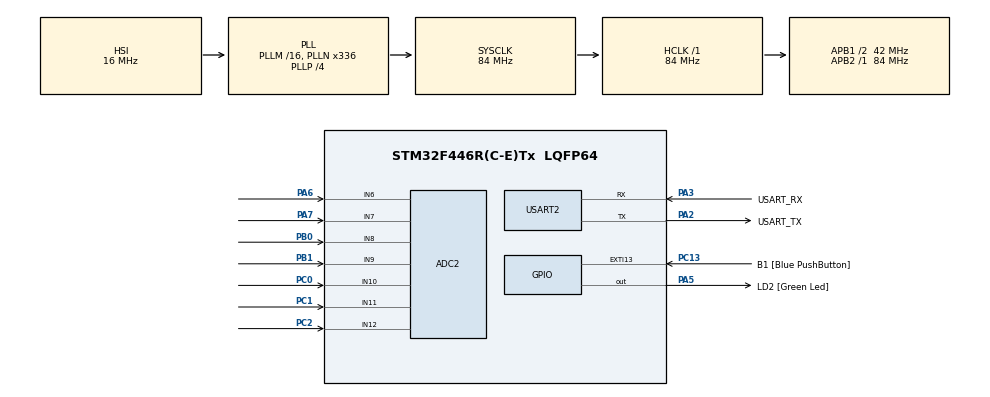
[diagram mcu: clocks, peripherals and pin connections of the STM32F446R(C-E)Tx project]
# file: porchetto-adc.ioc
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ADC2.Channel-2\#ChannelRegularConversion=ADC_CHANNEL_6
ADC2.Channel-3\#ChannelRegularConversion=ADC_CHANNEL_7
ADC2.Channel-4\#ChannelRegularConversion=ADC_CHANNEL_8
ADC2.Channel-5\#ChannelRegularConversion=ADC_CHANNEL_9
ADC2.Channel-6\#ChannelRegularConversion=ADC_CHANNEL_10
ADC2.Channel-7\#ChannelRegularConversion=ADC_CHANNEL_11
ADC2.Channel-8\#ChannelRegularConversion=ADC_CHANNEL_12
ADC2.ContinuousConvMode=DISABLE
ADC2.DMAContinuousRequests=DISABLE
ADC2.EOCSelection=ADC_EOC_SEQ_CONV
ADC2.NbrOfConversion=7
ADC2.NbrOfConversionFlag=1
ADC2.Rank-2\#ChannelRegularConversion=1
ADC2.Rank-3\#ChannelRegularConversion=2
ADC2.Rank-4\#ChannelRegularConversion=3
ADC2.Rank-5\#ChannelRegularConversion=4
ADC2.Rank-6\#ChannelRegularConversion=5
ADC2.Rank-7\#ChannelRegularConversion=6
ADC2.Rank-8\#ChannelRegularConversion=7
ADC2.SamplingTime-2\#ChannelRegularConversion=ADC_SAMPLETIME_28CYCLES
ADC2.SamplingTime-3\#ChannelRegularConversion=ADC_SAMPLETIME_28CYCLES
ADC2.SamplingTime-4\#ChannelRegularConversion=ADC_SAMPLETIME_28CYCLES
ADC2.SamplingTime-5\#ChannelRegularConversion=ADC_SAMPLETIME_28CYCLES
ADC2.SamplingTime-6\#ChannelRegularConversion=ADC_SAMPLETIME_28CYCLES
ADC2.SamplingTime-7\#ChannelRegularConversion=ADC_SAMPLETIME_28CYCLES
ADC2.SamplingTime-8\#ChannelRegularConversion=ADC_SAMPLETIME_28CYCLES
ADC2.ScanConvMode=ENABLE
Dma.ADC2.0.Direction=DMA_PERIPH_TO_MEMORY
Dma.ADC2.0.FIFOMode=DMA_FIFOMODE_DISABLE
Dma.ADC2.0.Instance=DMA2_Stream2
Dma.ADC2.0.MemDataAlignment=DMA_MDATAALIGN_HALFWORD
Dma.ADC2.0.MemInc=DMA_MINC_ENABLE
Dma.ADC2.0.Mode=DMA_NORMAL
Dma.ADC2.0.PeriphDataAlignment=DMA_PDATAALIGN_HALFWORD
Dma.ADC2.0.PeriphInc=DMA_PINC_DISABLE
Dma.ADC2.0.Priority=DMA_PRIORITY_LOW
Dma.Request0=ADC2
Mcu.Family=STM32F4
Mcu.Name=STM32F446R(C-E)Tx
Mcu.Package=LQFP64
NVIC.ADC_IRQn=true\:0\:0\:false\:false\:true\:true\:true\:true
NVIC.DMA2_Stream2_IRQn=true\:0\:0\:false\:false\:true\:false\:true\:true
NVIC.PriorityGroup=NVIC_PRIORITYGROUP_0
PA13.GPIO_Label=TMS
PA13.Mode=Serial_Wire
PA13.Signal=SYS_JTMS-SWDIO
PA14.GPIO_Label=TCK
PA14.Mode=Serial_Wire
PA14.Signal=SYS_JTCK-SWCLK
PA2.GPIO_Label=USART_TX
PA2.Mode=Asynchronous
PA2.Signal=USART2_TX
PA3.GPIO_Label=USART_RX
PA3.Mode=Asynchronous
PA3.Signal=USART2_RX
PA5.GPIO_Label=LD2 [Green Led]
PA5.Signal=GPIO_Output
PA6.Signal=ADCx_IN6
PA7.Signal=ADCx_IN7
PB0.Signal=ADCx_IN8
PB1.Signal=ADCx_IN9
PB3.GPIO_Label=SWO
PB3.Signal=SYS_JTDO-SWO
PC0.Signal=ADCx_IN10
PC1.Signal=ADCx_IN11
PC13.GPIO_Label=B1 [Blue PushButton]
PC13.GPIO_ModeDefaultEXTI=GPIO_MODE_IT_FALLING
PC13.Signal=GPXTI13
PC14-OSC32_IN.Mode=LSE-External-Oscillator
PC14-OSC32_IN.Signal=RCC_OSC32_IN
PC15-OSC32_OUT.Mode=LSE-External-Oscillator
PC15-OSC32_OUT.Signal=RCC_OSC32_OUT
PC2.Signal=ADCx_IN12
PH0-OSC_IN.Mode=HSE-External-Oscillator
PH0-OSC_IN.Signal=RCC_OSC_IN
PH1-OSC_OUT.Mode=HSE-External-Oscillator
PH1-OSC_OUT.Signal=RCC_OSC_OUT
ProjectManager.HeapSize=0x200
ProjectManager.StackSize=0x400
ProjectManager.TargetToolchain=Makefile
RCC.48MHZClocksFreq_Value=84000000
RCC.AHBFreq_Value=84000000
RCC.APB1CLKDivider=RCC_HCLK_DIV2
RCC.APB1Freq_Value=42000000
RCC.APB1TimFreq_Value=84000000
RCC.APB2Freq_Value=84000000
RCC.APB2TimFreq_Value=84000000
RCC.CortexFreq_Value=84000000
RCC.FLatency-AdvancedSettings=FLASH_LATENCY_2
RCC.HCLKFreq_Value=84000000
RCC.HSE_VALUE=8000000
RCC.HSI_VALUE=16000000
RCC.PLLN=336
RCC.PLLP=RCC_PLLP_DIV4
RCC.SYSCLKFreq_VALUE=84000000
RCC.SYSCLKSource=RCC_SYSCLKSOURCE_PLLCLK
RCC.USBFreq_Value=168000000
RCC.VCOOutputFreq_Value=336000000
SH.ADCx_IN10.0=ADC2_IN10,IN10
SH.ADCx_IN11.0=ADC2_IN11,IN11
SH.ADCx_IN12.0=ADC2_IN12,IN12
SH.ADCx_IN6.0=ADC2_IN6,IN6
SH.ADCx_IN7.0=ADC2_IN7,IN7
SH.ADCx_IN8.0=ADC2_IN8,IN8
SH.ADCx_IN9.0=ADC2_IN9,IN9
USART2.VirtualMode=VM_ASYNC
board=NUCLEO-F446RE

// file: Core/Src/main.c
/* USER CODE BEGIN Header */
/**
  ******************************************************************************
  * @file           : main.c
  * @brief          : Main program body
  ******************************************************************************
  * @attention
  *
  * Copyright (c) 2025 STMicroelectronics.
  * All rights reserved.
  *
  * This software is licensed under terms that can be found in the LICENSE file
  * in the root directory of this software component.
  * If no LICENSE file comes with this software, it is provided AS-IS.
  *
  ******************************************************************************
  */
/* USER CODE END Header */
#include "main.h"
#include "adc.h"
#include "dma.h"
#include "usart.h"
#include "gpio.h"

/* USER CODE BEGIN Includes */
#include <string.h>
#include <stdio.h>
/* USER CODE END Includes */

/* USER CODE BEGIN PD */
#define ADC_CHANNELS 7
/* USER CODE END PD */

/* USER CODE BEGIN PV */
uint16_t adc_values[ADC_CHANNELS];
char msg[100] = {'\0'};

/* USER CODE END PV */

void SystemClock_Config(void);

/* USER CODE BEGIN 0 */

/**
 * callback function for completed conversion of all 7 channels
 */
void HAL_ADC_ConvCpltCallback(ADC_HandleTypeDef *hadc){
  sprintf(msg, "IN6: %u, IN7: %u, IN8: %u, IN9: %u, IN10: %u, IN11: %u, IN12: %u\r\n",
    adc_values[0], adc_values[1], adc_values[2], adc_values[3], adc_values[4], adc_values[5], adc_values[6]);

  HAL_UART_Transmit(&huart2, (uint8_t*)msg, strlen(msg), 100);

  HAL_ADC_Start_DMA(hadc, (uint32_t*)adc_values, ADC_CHANNELS);
}

/* USER CODE END 0 */

int main(void)
{

  /* MCU Configuration--------------------------------------------------------*/

  /* Reset of all peripherals, Initializes the Flash interface and the Systick. */
  HAL_Init();

  /* Configure the system clock */
  SystemClock_Config();

  /* Initialize all configured peripherals */
  MX_GPIO_Init();
  MX_DMA_Init();
  MX_USART2_UART_Init();
  MX_ADC2_Init();
  /* USER CODE BEGIN 2 */
  HAL_ADC_Start_DMA(&hadc2, (uint32_t*)adc_values, ADC_CHANNELS);
  /* USER CODE END 2 */

  /* Infinite loop */
  while (1)
  {

  }
}

void SystemClock_Config(void)
{
  RCC_OscInitTypeDef RCC_OscInitStruct = {0};
  RCC_ClkInitTypeDef RCC_ClkInitStruct = {0};

  /** Configure the main internal regulator output voltage
  */
  __HAL_RCC_PWR_CLK_ENABLE();
  __HAL_PWR_VOLTAGESCALING_CONFIG(PWR_REGULATOR_VOLTAGE_SCALE3);

  /** Initializes the RCC Oscillators according to the specified parameters
  * in the RCC_OscInitTypeDef structure.
  */
  RCC_OscInitStruct.OscillatorType = RCC_OSCILLATORTYPE_HSI;
  RCC_OscInitStruct.HSIState = RCC_HSI_ON;
  RCC_OscInitStruct.HSICalibrationValue = RCC_HSICALIBRATION_DEFAULT;
  RCC_OscInitStruct.PLL.PLLState = RCC_PLL_ON;
  RCC_OscInitStruct.PLL.PLLSource = RCC_PLLSOURCE_HSI;
  RCC_OscInitStruct.PLL.PLLM = 16;
  RCC_OscInitStruct.PLL.PLLN = 336;
  RCC_OscInitStruct.PLL.PLLP = RCC_PLLP_DIV4;
  RCC_OscInitStruct.PLL.PLLQ = 2;
  RCC_OscInitStruct.PLL.PLLR = 2;
  if (HAL_RCC_OscConfig(&RCC_OscInitStruct) != HAL_OK)
  {
    Error_Handler();
  }

  /** Initializes the CPU, AHB and APB buses clocks
  */
  RCC_ClkInitStruct.ClockType = RCC_CLOCKTYPE_HCLK|RCC_CLOCKTYPE_SYSCLK
                              |RCC_CLOCKTYPE_PCLK1|RCC_CLOCKTYPE_PCLK2;
  RCC_ClkInitStruct.SYSCLKSource = RCC_SYSCLKSOURCE_PLLCLK;
  RCC_ClkInitStruct.AHBCLKDivider = RCC_SYSCLK_DIV1;
  RCC_ClkInitStruct.APB1CLKDivider = RCC_HCLK_DIV2;
  RCC_ClkInitStruct.APB2CLKDivider = RCC_HCLK_DIV1;

  if (HAL_RCC_ClockConfig(&RCC_ClkInitStruct, FLASH_LATENCY_2) != HAL_OK)
  {
    Error_Handler();
  }
}

void Error_Handler(void)
{
  __disable_irq();
  while (1)
  {
  }
}
